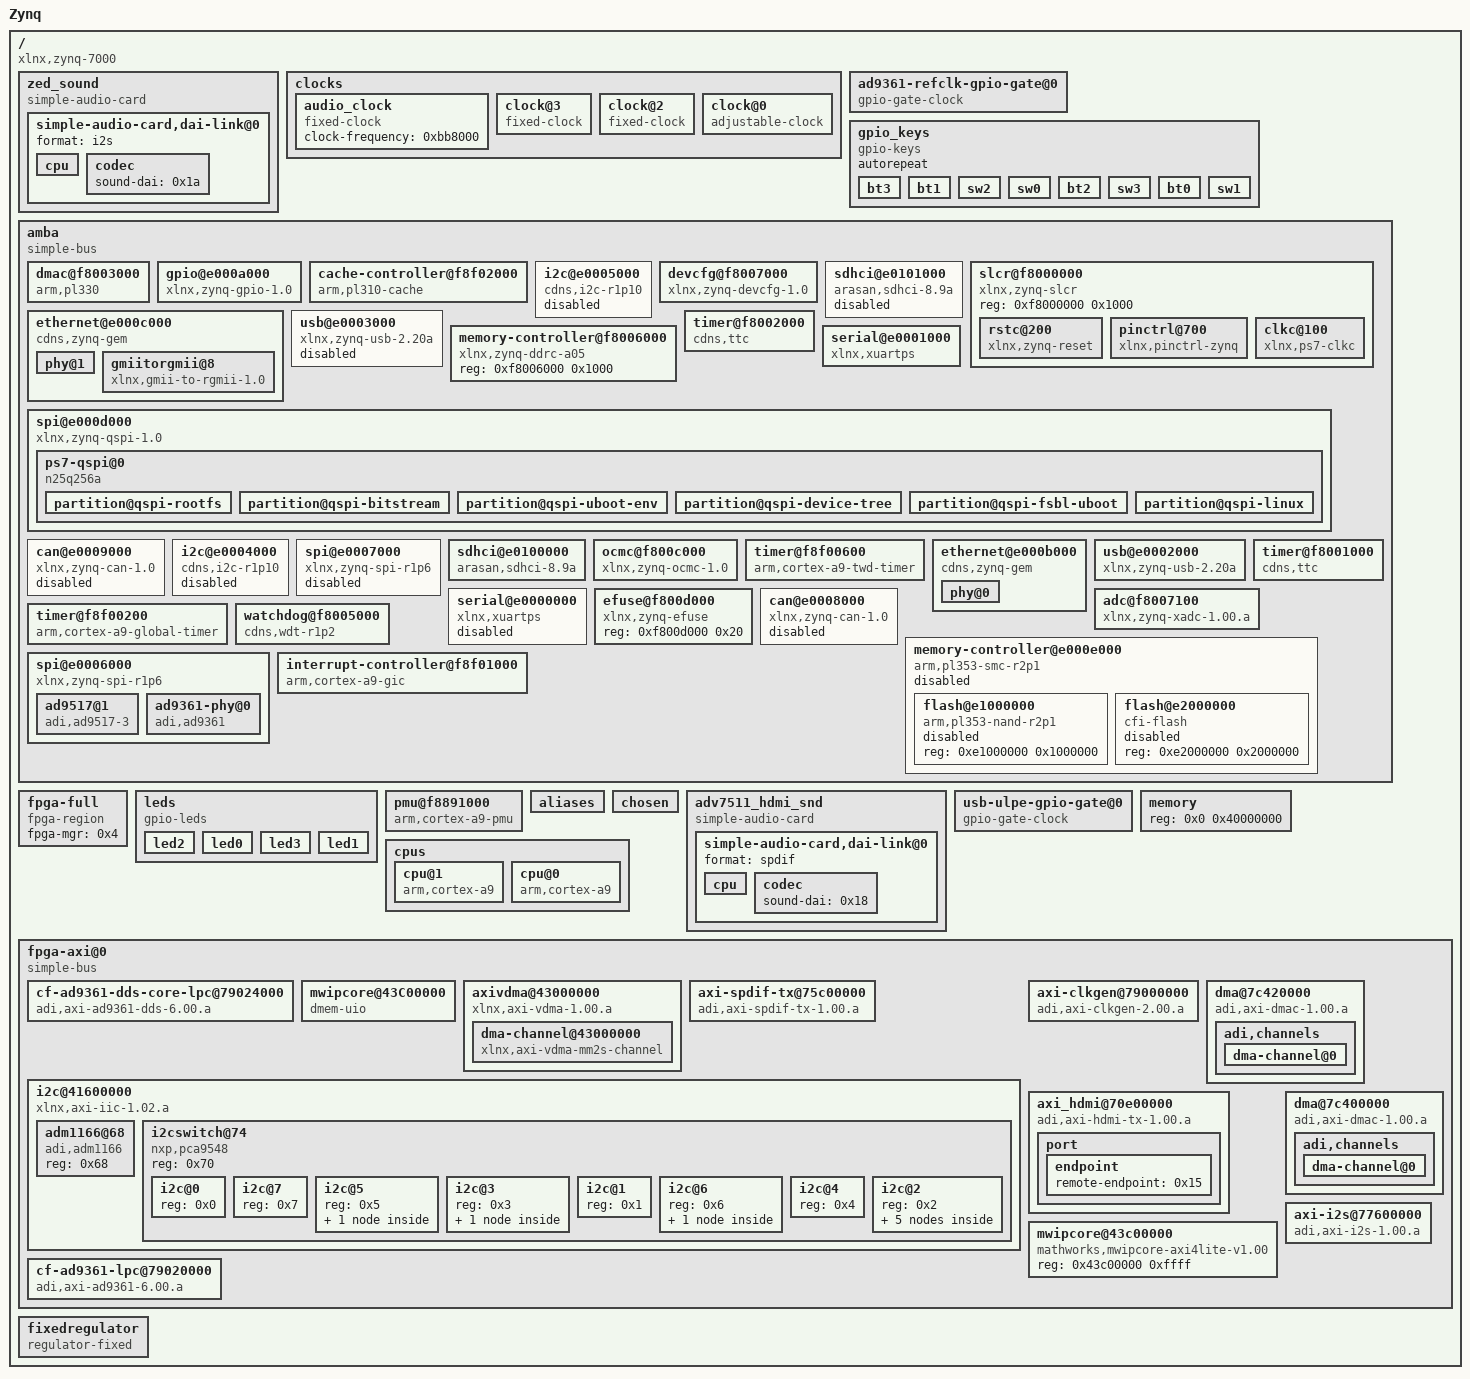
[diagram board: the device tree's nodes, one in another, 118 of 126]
/dts-v1/;

/ {
	compatible = "xlnx,zynq-7000";
	model = "Zynq", "PicoZed", "SDR2", "Board";
	interrupt-parent = <0x1>;
	#address-cells = <0x1>;
	#size-cells = <0x1>;

	zed_sound {
		simple-audio-card,name = "ZED ADAU1761";
		simple-audio-card,routing = "Line Out", "LOUT", "Line Out", "ROUT", "Headphone Out", "LHP", "Headphone Out", "RHP", "Mic In", "MICBIAS", "LINN", "Mic In", "RINN", "Mic In", "LAUX", "Line In", "RAUX", "Line In";
		compatible = "simple-audio-card";
		simple-audio-card,widgets = "Microphone", "Mic In", "Headphone", "Headphone Out", "Line", "Line In", "Line", "Line Out";

		simple-audio-card,dai-link@0 {
			format = "i2s";

			cpu {
				frame-master;
				bitclock-master;
				sound-dai = <0x19>;
			};

			codec {
				sound-dai = <0x1a>;
			};
		};
	};

	clocks {

		audio_clock {
			compatible = "fixed-clock";
			#clock-cells = <0x0>;
			phandle = <0xf>;
			clock-frequency = <0xbb8000>;
			linux,phandle = <0xf>;
		};

		clock@3 {
			compatible = "fixed-clock";
			#clock-cells = <0x0>;
			phandle = <0x7>;
			clock-output-names = "ad9517_refclk";
			clock-frequency = <0x17d7840>;
			linux,phandle = <0x7>;
		};

		clock@2 {
			compatible = "fixed-clock";
			#clock-cells = <0x0>;
			phandle = <0xd>;
			clock-output-names = "24MHz";
			clock-frequency = <0x16e3600>;
			linux,phandle = <0xd>;
		};

		clock@0 {
			compatible = "adjustable-clock";
			#clock-cells = <0x0>;
			phandle = <0xc>;
			clock-accuracy = <0x30d40>;
			clock-output-names = "XO_40MHz";
			clock-frequency = <0x2625976>;
			linux,phandle = <0xc>;
		};
	};

	ad9361-refclk-gpio-gate@0 {
		compatible = "gpio-gate-clock";
		clocks = <0xc>;
		#clock-cells = <0x0>;
		phandle = <0x5>;
		clk-set-rate-parent-enable;
		clock-output-names = "ad9361_ext_refclk";
		linux,phandle = <0x5>;
		enable-gpios = <0x6 0x69 0x0>;
	};

	gpio_keys {
		compatible = "gpio-keys";
		autorepeat;
		#address-cells = <0x1>;
		#size-cells = <0x0>;

		bt3 {
			gpios = <0x6 0x39 0x0>;
			label = "BT3";
			linux,code = <0x1>;
		};

		bt1 {
			gpios = <0x6 0x37 0x0>;
			label = "BT1";
			linux,code = <0x6a>;
		};

		sw2 {
			gpios = <0x6 0x40 0x0>;
			label = "SW2";
			linux,input-type = <0x5>;
			linux,code = <0x2>;
		};

		sw0 {
			gpios = <0x6 0x41 0x0>;
			label = "SW0";
			linux,input-type = <0x5>;
			linux,code = <0x0>;
		};

		bt2 {
			gpios = <0x6 0x38 0x0>;
			label = "BT2";
			linux,code = <0x1c>;
		};

		sw3 {
			gpios = <0x6 0x3f 0x0>;
			label = "SW3";
			linux,input-type = <0x5>;
			linux,code = <0x3>;
		};

		bt0 {
			gpios = <0x6 0x36 0x0>;
			label = "BT0";
			linux,code = <0x69>;
		};

		sw1 {
			gpios = <0x6 0x3e 0x0>;
			label = "SW1";
			linux,input-type = <0x5>;
			linux,code = <0x1>;
		};
	};

	amba {
		compatible = "simple-bus";
		ranges;
		interrupt-parent = <0x1>;
		#address-cells = <0x1>;
		#size-cells = <0x1>;
		u-boot,dm-pre-reloc;

		dmac@f8003000 {
			#dma-cells = <0x1>;
			compatible = "arm,pl330", "arm,primecell";
			clocks = <0x2 0x1b>;
			clock-names = "apb_pclk";
			#dma-requests = <0x4>;
			interrupt-parent = <0x1>;
			interrupts = <0x0 0xd 0x4 0x0 0xe 0x4 0x0 0xf 0x4 0x0 0x10 0x4 0x0 0x11 0x4 0x0 0x28 0x4 0x0 0x29 0x4 0x0 0x2a 0x4 0x0 0x2b 0x4>;
			phandle = <0x16>;
			reg = <0xf8003000 0x1000>;
			linux,phandle = <0x16>;
			#dma-channels = <0x8>;
			interrupt-names = "abort", "dma0", "dma1", "dma2", "dma3", "dma4", "dma5", "dma6", "dma7";
		};

		gpio@e000a000 {
			compatible = "xlnx,zynq-gpio-1.0";
			clocks = <0x2 0x2a>;
			gpio-controller;
			#interrupt-cells = <0x2>;
			interrupt-parent = <0x1>;
			interrupts = <0x0 0x14 0x4>;
			phandle = <0x6>;
			reg = <0xe000a000 0x1000>;
			#gpio-cells = <0x2>;
			linux,phandle = <0x6>;
			interrupt-controller;
		};

		cache-controller@f8f02000 {
			compatible = "arm,pl310-cache";
			cache-level = <0x2>;
			cache-unified;
			arm,data-latency = <0x3 0x2 0x2>;
			interrupts = <0x0 0x2 0x4>;
			reg = <0xf8f02000 0x1000>;
			arm,tag-latency = <0x2 0x2 0x2>;
		};

		i2c@e0005000 {
			compatible = "cdns,i2c-r1p10";
			clocks = <0x2 0x27>;
			status = "disabled";
			interrupt-parent = <0x1>;
			#address-cells = <0x1>;
			interrupts = <0x0 0x30 0x4>;
			#size-cells = <0x0>;
			reg = <0xe0005000 0x1000>;
		};

		devcfg@f8007000 {
			compatible = "xlnx,zynq-devcfg-1.0";
			clocks = <0x2 0xc 0x2 0xf 0x2 0x10 0x2 0x11 0x2 0x12>;
			clock-names = "ref_clk", "fclk0", "fclk1", "fclk2", "fclk3";
			interrupt-parent = <0x1>;
			interrupts = <0x0 0x8 0x4>;
			phandle = <0x4>;
			reg = <0xf8007000 0x100>;
			syscon = <0xb>;
			linux,phandle = <0x4>;
		};

		sdhci@e0101000 {
			compatible = "arasan,sdhci-8.9a";
			clocks = <0x2 0x16 0x2 0x21>;
			clock-names = "clk_xin", "clk_ahb";
			status = "disabled";
			interrupt-parent = <0x1>;
			interrupts = <0x0 0x2f 0x4>;
			reg = <0xe0101000 0x1000>;
			broken-adma2;
		};

		slcr@f8000000 {
			compatible = "xlnx,zynq-slcr", "syscon", "simple-mfd";
			ranges;
			#address-cells = <0x1>;
			#size-cells = <0x1>;
			phandle = <0xb>;
			reg = <0xf8000000 0x1000>;
			linux,phandle = <0xb>;

			rstc@200 {
				compatible = "xlnx,zynq-reset";
				#reset-cells = <0x1>;
				reg = <0x200 0x48>;
				syscon = <0xb>;
			};

			pinctrl@700 {
				compatible = "xlnx,pinctrl-zynq";
				reg = <0x700 0x200>;
				syscon = <0xb>;
			};

			clkc@100 {
				compatible = "xlnx,ps7-clkc";
				ps-clk-frequency = <0x1fca055>;
				#clock-cells = <0x1>;
				phandle = <0x2>;
				reg = <0x100 0x100>;
				clock-output-names = "armpll", "ddrpll", "iopll", "cpu_6or4x", "cpu_3or2x", "cpu_2x", "cpu_1x", "ddr2x", "ddr3x", "dci", "lqspi", "smc", "pcap", "gem0", "gem1", "fclk0", "fclk1", "fclk2", "fclk3", "can0", "can1", "sdio0", "sdio1", "uart0", "uart1", "spi0", "spi1", "dma", "usb0_aper", "usb1_aper", "gem0_aper", "gem1_aper", "sdio0_aper", "sdio1_aper", "spi0_aper", "spi1_aper", "can0_aper", "can1_aper", "i2c0_aper", "i2c1_aper", "uart0_aper", "uart1_aper", "gpio_aper", "lqspi_aper", "smc_aper", "swdt", "dbg_trc", "dbg_apb";
				fclk-enable = <0xf>;
				linux,phandle = <0x2>;
			};
		};

		ethernet@e000c000 {
			phy-handle = <0x9>;
			compatible = "cdns,zynq-gem", "cdns,gem";
			clocks = <0x2 0x1f 0x2 0x1f 0x2 0xe>;
			clock-names = "pclk", "hclk", "tx_clk";
			status = "okay";
			#address-cells = <0x1>;
			interrupts = <0x0 0x2d 0x4>;
			#size-cells = <0x0>;
			reg = <0xe000c000 0x1000>;
			phy-mode = "gmii";

			phy@1 {
				device_type = "ethernet-phy";
				phandle = <0xa>;
				marvell,reg-init = <0x3 0x10 0xff00 0x1e 0x3 0x11 0xfff0 0x0>;
				reg = <0x1>;
				linux,phandle = <0xa>;
			};

			gmiitorgmii@8 {
				phy-handle = <0xa>;
				compatible = "xlnx,gmii-to-rgmii-1.0";
				phandle = <0x9>;
				reg = <0x8>;
				linux,phandle = <0x9>;
			};
		};

		usb@e0003000 {
			compatible = "xlnx,zynq-usb-2.20a", "chipidea,usb2";
			clocks = <0x2 0x1d>;
			status = "disabled";
			interrupt-parent = <0x1>;
			interrupts = <0x0 0x2c 0x4>;
			reg = <0xe0003000 0x1000>;
			phy_type = "ulpi";
		};

		memory-controller@f8006000 {
			compatible = "xlnx,zynq-ddrc-a05";
			reg = <0xf8006000 0x1000>;
		};

		timer@f8002000 {
			compatible = "cdns,ttc";
			clocks = <0x2 0x6>;
			interrupt-parent = <0x1>;
			interrupts = <0x0 0x25 0x4 0x0 0x26 0x4 0x0 0x27 0x4>;
			reg = <0xf8002000 0x1000>;
		};

		serial@e0001000 {
			compatible = "xlnx,xuartps", "cdns,uart-r1p8";
			clocks = <0x2 0x18 0x2 0x29>;
			clock-names = "uart_clk", "pclk";
			status = "okay";
			interrupts = <0x0 0x32 0x4>;
			reg = <0xe0001000 0x1000>;
		};

		spi@e000d000 {
			compatible = "xlnx,zynq-qspi-1.0";
			clocks = <0x2 0xa 0x2 0x2b>;
			clock-names = "ref_clk", "pclk";
			status = "okay";
			interrupt-parent = <0x1>;
			#address-cells = <0x1>;
			interrupts = <0x0 0x13 0x4>;
			#size-cells = <0x0>;
			is-dual = <0x0>;
			reg = <0xe000d000 0x1000>;
			num-cs = <0x1>;

			ps7-qspi@0 {
				compatible = "n25q256a", "jedec,spi-nor";
				spi-rx-bus-width = <0x4>;
				#address-cells = <0x1>;
				#size-cells = <0x1>;
				reg = <0x0>;
				spi-tx-bus-width = <0x1>;
				spi-max-frequency = <0x2faf080>;

				partition@qspi-rootfs {
					label = "qspi-rootfs";
					reg = <0x620000 0xce0000>;
				};

				partition@qspi-bitstream {
					label = "qspi-bitstream";
					reg = <0x1300000 0xd00000>;
				};

				partition@qspi-uboot-env {
					label = "qspi-uboot-env";
					reg = <0xe0000 0x20000>;
				};

				partition@qspi-device-tree {
					label = "qspi-device-tree";
					reg = <0x600000 0x20000>;
				};

				partition@qspi-fsbl-uboot {
					label = "qspi-fsbl-uboot";
					reg = <0x0 0xe0000>;
				};

				partition@qspi-linux {
					label = "qspi-linux";
					reg = <0x100000 0x500000>;
				};
			};
		};

		can@e0009000 {
			compatible = "xlnx,zynq-can-1.0";
			clocks = <0x2 0x14 0x2 0x25>;
			tx-fifo-depth = <0x40>;
			clock-names = "can_clk", "pclk";
			status = "disabled";
			interrupt-parent = <0x1>;
			interrupts = <0x0 0x33 0x4>;
			reg = <0xe0009000 0x1000>;
			rx-fifo-depth = <0x40>;
		};

		i2c@e0004000 {
			compatible = "cdns,i2c-r1p10";
			clocks = <0x2 0x26>;
			status = "disabled";
			interrupt-parent = <0x1>;
			#address-cells = <0x1>;
			interrupts = <0x0 0x19 0x4>;
			#size-cells = <0x0>;
			reg = <0xe0004000 0x1000>;
		};

		spi@e0007000 {
			compatible = "xlnx,zynq-spi-r1p6";
			clocks = <0x2 0x1a 0x2 0x23>;
			clock-names = "ref_clk", "pclk";
			status = "disabled";
			interrupt-parent = <0x1>;
			#address-cells = <0x1>;
			interrupts = <0x0 0x31 0x4>;
			#size-cells = <0x0>;
			reg = <0xe0007000 0x1000>;
		};

		sdhci@e0100000 {
			compatible = "arasan,sdhci-8.9a";
			clocks = <0x2 0x15 0x2 0x20>;
			clock-names = "clk_xin", "clk_ahb";
			status = "okay";
			interrupt-parent = <0x1>;
			interrupts = <0x0 0x18 0x4>;
			disable-wp;
			reg = <0xe0100000 0x1000>;
			broken-adma2;
		};

		ocmc@f800c000 {
			compatible = "xlnx,zynq-ocmc-1.0";
			interrupt-parent = <0x1>;
			interrupts = <0x0 0x3 0x4>;
			reg = <0xf800c000 0x1000>;
		};

		timer@f8f00600 {
			compatible = "arm,cortex-a9-twd-timer";
			clocks = <0x2 0x4>;
			interrupt-parent = <0x1>;
			interrupts = <0x1 0xd 0x301>;
			reg = <0xf8f00600 0x20>;
		};

		ethernet@e000b000 {
			phy-handle = <0x8>;
			compatible = "cdns,zynq-gem", "cdns,gem";
			clocks = <0x2 0x1e 0x2 0x1e 0x2 0xd>;
			local-mac-address = [00 02 b5 01 c5 57];
			clock-names = "pclk", "hclk", "tx_clk";
			status = "okay";
			#address-cells = <0x1>;
			interrupts = <0x0 0x16 0x4>;
			#size-cells = <0x0>;
			reg = <0xe000b000 0x1000>;
			phy-mode = "rgmii-id";

			phy@0 {
				device_type = "ethernet-phy";
				phandle = <0x8>;
				marvell,reg-init = <0x3 0x10 0xff00 0x1e 0x3 0x11 0xfff0 0x0>;
				reg = <0x0>;
				linux,phandle = <0x8>;
			};
		};

		usb@e0002000 {
			compatible = "xlnx,zynq-usb-2.20a", "chipidea,usb2";
			clocks = <0x2 0x1c>;
			status = "okay";
			interrupt-parent = <0x1>;
			interrupts = <0x0 0x15 0x4>;
			xlnx,phy-reset-gpio = <0x6 0x7 0x0>;
			reg = <0xe0002000 0x1000>;
			dr_mode = "host";
			phy_type = "ulpi";
		};

		timer@f8001000 {
			compatible = "cdns,ttc";
			clocks = <0x2 0x6>;
			interrupt-parent = <0x1>;
			interrupts = <0x0 0xa 0x4 0x0 0xb 0x4 0x0 0xc 0x4>;
			reg = <0xf8001000 0x1000>;
		};

		serial@e0000000 {
			compatible = "xlnx,xuartps", "cdns,uart-r1p8";
			clocks = <0x2 0x17 0x2 0x28>;
			clock-names = "uart_clk", "pclk";
			status = "disabled";
			interrupts = <0x0 0x1b 0x4>;
			reg = <0xe0000000 0x1000>;
		};

		efuse@f800d000 {
			compatible = "xlnx,zynq-efuse";
			reg = <0xf800d000 0x20>;
		};

		can@e0008000 {
			compatible = "xlnx,zynq-can-1.0";
			clocks = <0x2 0x13 0x2 0x24>;
			tx-fifo-depth = <0x40>;
			clock-names = "can_clk", "pclk";
			status = "disabled";
			interrupt-parent = <0x1>;
			interrupts = <0x0 0x1c 0x4>;
			reg = <0xe0008000 0x1000>;
			rx-fifo-depth = <0x40>;
		};

		adc@f8007100 {
			compatible = "xlnx,zynq-xadc-1.00.a";
			clocks = <0x2 0xc>;
			interrupt-parent = <0x1>;
			interrupts = <0x0 0x7 0x4>;
			reg = <0xf8007100 0x20>;
		};

		timer@f8f00200 {
			compatible = "arm,cortex-a9-global-timer";
			clocks = <0x2 0x4>;
			interrupt-parent = <0x1>;
			interrupts = <0x1 0xb 0x301>;
			reg = <0xf8f00200 0x20>;
		};

		memory-controller@e000e000 {
			compatible = "arm,pl353-smc-r2p1";
			clocks = <0x2 0xb 0x2 0x2c>;
			clock-names = "memclk", "aclk";
			ranges;
			status = "disabled";
			interrupt-parent = <0x1>;
			#address-cells = <0x1>;
			interrupts = <0x0 0x12 0x4>;
			#size-cells = <0x1>;
			reg = <0xe000e000 0x1000>;

			flash@e1000000 {
				compatible = "arm,pl353-nand-r2p1";
				status = "disabled";
				#address-cells = <0x1>;
				#size-cells = <0x1>;
				reg = <0xe1000000 0x1000000>;
			};

			flash@e2000000 {
				compatible = "cfi-flash";
				status = "disabled";
				#address-cells = <0x1>;
				#size-cells = <0x1>;
				reg = <0xe2000000 0x2000000>;
			};
		};

		watchdog@f8005000 {
			compatible = "cdns,wdt-r1p2";
			clocks = <0x2 0x2d>;
			interrupt-parent = <0x1>;
			interrupts = <0x0 0x9 0x1>;
			reg = <0xf8005000 0x1000>;
			timeout-sec = <0xa>;
		};

		spi@e0006000 {
			compatible = "xlnx,zynq-spi-r1p6";
			clocks = <0x2 0x19 0x2 0x22>;
			clock-names = "ref_clk", "pclk";
			status = "okay";
			interrupt-parent = <0x1>;
			#address-cells = <0x1>;
			interrupts = <0x0 0x1a 0x4>;
			#size-cells = <0x0>;
			reg = <0xe0006000 0x1000>;

			ad9517@1 {
				compatible = "adi,ad9517-3";
				clocks = <0x7 0x7>;
				clock-names = "refclk", "clkin";
				firmware = "pzsdr-fmc-ad9517.stp";
				#address-cells = <0x1>;
				#size-cells = <0x0>;
				#clock-cells = <0x1>;
				reg = <0x1>;
				clock-output-names = "out0", "out1", "out2", "out3", "out4", "out5", "out6", "out7";
				spi-max-frequency = <0x989680>;
			};

			ad9361-phy@0 {
				adi,mgc-inc-gain-step = <0x2>;
				adi,rf-rx-bandwidth-hz = <0x112a880>;
				adi,gc-dec-pow-measurement-duration = <0x2000>;
				adi,agc-adc-large-overload-exceed-counter = <0xa>;
				adi,pp-tx-swap-enable;
				adi,rssi-wait = <0x1>;
				adi,aux-dac-manual-mode-enable;
				compatible = "adi,ad9361";
				adi,gc-adc-small-overload-thresh = <0x2f>;
				clocks = <0x5 0x0>;
				adi,agc-lmt-overload-large-exceed-counter = <0xa>;
				adi,temp-sense-offset-signed = <0xce>;
				adi,gc-rx1-mode = <0x2>;
				adi,2rx-2tx-mode-enable;
				adi,fagc-use-last-lock-level-for-set-gain-enable;
				adi,lvds-bias-mV = <0x96>;
				en_agc-gpios = <0x6 0x62 0x0>;
				adi,fagc-rst-gla-engergy-lost-goto-optim-gain-enable;
				adi,fagc-rst-gla-large-adc-overload-enable;
				adi,rssi-duration = <0x3e8>;
				adi,mgc-dec-gain-step = <0x2>;
				adi,fagc-lpf-final-settling-steps = <0x1>;
				adi,fagc-rst-gla-large-lmt-overload-enable;
				adi,aux-dac2-default-value-mV = <0x0>;
				spi-cpha;
				adi,fagc-final-overrange-count = <0x3>;
				adi,fagc-lock-level-gain-increase-upper-limit = <0x5>;
				adi,tx-synthesizer-frequency-hz = <0x0 0x92080880>;
				adi,agc-attack-delay-extra-margin-us = <0x1>;
				adi,rx-data-delay = <0x4>;
				adi,fagc-rst-gla-engergy-lost-sig-thresh-exceeded-enable;
				clock-names = "ad9361_ext_refclk";
				adi,tx-path-clock-frequencies = <0x3a980000 0x7530000 0x7530000 0x3a98000 0x1d4c000 0x1d4c000>;
				adi,agc-lmt-overload-small-exceed-counter = <0xa>;
				adi,temp-sense-periodic-measurement-enable;
				adi,fagc-state-wait-time-ns = <0x104>;
				adi,fagc-gain-index-type-after-exit-rx-mode = <0x0>;
				adi,tx-fb-clock-delay = <0x7>;
				adi,fagc-dec-pow-measurement-duration = <0x40>;
				adi,gc-adc-large-overload-thresh = <0x3a>;
				txnrx-gpios = <0x6 0x66 0x0>;
				adi,rssi-restart-mode = <0x3>;
				adi,fagc-power-measurement-duration-in-state5 = <0x40>;
				adi,ctrl-outs-enable-mask = <0xff>;
				adi,rf-tx-bandwidth-hz = <0x112a880>;
				adi,fagc-lp-thresh-increment-time = <0x5>;
				adi,aux-dac1-tx-delay-us = <0x0>;
				adi,tx-rf-port-input-select = <0x0>;
				adi,agc-outer-thresh-low-inc-steps = <0x2>;
				#address-cells = <0x1>;
				adi,rx-synthesizer-frequency-hz = <0x0 0x8f0d1800>;
				reset-gpios = <0x6 0x64 0x0>;
				adi,fagc-rst-gla-if-en-agc-pulled-high-mode = <0x0>;
				adi,rx-frame-pulse-mode-enable;
				#size-cells = <0x0>;
				adi,agc-inner-thresh-low-inc-steps = <0x1>;
				adi,pp-rx-swap-enable;
				#clock-cells = <0x1>;
				adi,rx-path-clock-frequencies = <0x3a980000 0xea60000 0x7530000 0x3a98000 0x1d4c000 0x1d4c000>;
				phandle = <0x11>;
				adi,fagc-lp-thresh-increment-steps = <0x1>;
				adi,aux-dac1-default-value-mV = <0x0>;
				adi,fagc-rst-gla-stronger-sig-thresh-above-ll = <0xa>;
				adi,fagc-energy-lost-stronger-sig-gain-lock-exit-cnt = <0x8>;
				adi,tx-attenuation-mdB = <0x2710>;
				adi,digital-interface-tune-skip-mode = <0x0>;
				adi,agc-inner-thresh-high = <0xa>;
				adi,ctrl-outs-index = <0x0>;
				adi,agc-gain-update-interval-us = <0x3e8>;
				adi,aux-dac2-tx-delay-us = <0x0>;
				adi,fagc-optimized-gain-offset = <0x5>;
				adi,fagc-rst-gla-stronger-sig-thresh-exceeded-enable;
				adi,agc-inner-thresh-high-dec-steps = <0x1>;
				adi,aux-dac1-rx-delay-us = <0x0>;
				reg = <0x0>;
				adi,gc-low-power-thresh = <0x18>;
				adi,xo-disable-use-ext-refclk-enable;
				adi,agc-outer-thresh-low = <0x12>;
				clock-output-names = "rx_sampl_clk", "tx_sampl_clk";
				adi,mgc-split-table-ctrl-inp-gain-mode = <0x0>;
				adi,fagc-lmt-final-settling-steps = <0x1>;
				adi,lvds-mode-enable;
				adi,gc-lmt-overload-high-thresh = <0x320>;
				adi,agc-lmt-overload-large-inc-steps = <0x2>;
				adi,fagc-lock-level-lmt-gain-increase-enable;
				adi,rx-rf-port-input-select = <0x0>;
				adi,agc-inner-thresh-low = <0xc>;
				adi,fagc-rst-gla-engergy-lost-sig-thresh-below-ll = <0xa>;
				adi,agc-outer-thresh-high-dec-steps = <0x2>;
				adi,lvds-rx-onchip-termination-enable;
				linux,phandle = <0x11>;
				sync-gpios = <0x6 0x63 0x0>;
				enable-gpios = <0x6 0x65 0x0>;
				spi-max-frequency = <0x989680>;
				adi,rssi-delay = <0x1>;
				adi,agc-outer-thresh-high = <0x5>;
				adi,frequency-division-duplex-mode-enable;
				adi,aux-dac2-rx-delay-us = <0x0>;
				adi,agc-adc-large-overload-inc-steps = <0x2>;
				adi,gc-lmt-overload-low-thresh = <0x2c0>;
				adi,gc-adc-ovr-sample-size = <0x4>;
				adi,gc-rx2-mode = <0x2>;
				adi,temp-sense-measurement-interval-ms = <0x3e8>;
				adi,fagc-lock-level = <0xa>;
				adi,agc-adc-small-overload-exceed-counter = <0xa>;
			};
		};

		interrupt-controller@f8f01000 {
			compatible = "arm,cortex-a9-gic";
			#interrupt-cells = <0x3>;
			phandle = <0x1>;
			reg = <0xf8f01000 0x1000 0xf8f00100 0x100>;
			linux,phandle = <0x1>;
			interrupt-controller;
		};
	};

	fpga-full {
		compatible = "fpga-region";
		fpga-mgr = <0x4>;
		ranges;
		#address-cells = <0x1>;
		#size-cells = <0x1>;
	};

	leds {
		compatible = "gpio-leds";

		led2 {
			gpios = <0x6 0x3a 0x0>;
			label = "led2:red";
		};

		led0 {
			gpios = <0x6 0x3d 0x0>;
			label = "led0:red";
		};

		led3 {
			gpios = <0x6 0x3c 0x0>;
			label = "led3:red";
		};

		led1 {
			gpios = <0x6 0x3b 0x0>;
			label = "led1:red";
		};
	};

	pmu@f8891000 {
		compatible = "arm,cortex-a9-pmu";
		interrupt-parent = <0x1>;
		interrupts = <0x0 0x5 0x4 0x0 0x6 0x4>;
		reg = <0xf8891000 0x1000 0xf8893000 0x1000>;
	};

	aliases {
		ethernet0 = "/amba/ethernet@e000b000";
		ethernet1 = "/amba/ethernet@e000c000";
		serial0 = "/amba/serial@e0001000";
	};

	chosen {
		bootargs = "console=ttyPS0,115200 root=/dev/mmcblk0p2 rw earlyprintk rootfstype=ext4 rootwait";
		linux,stdout-path = "/amba@0/uart@E0001000";
	};

	adv7511_hdmi_snd {
		simple-audio-card,name = "HDMI monitor";
		simple-audio-card,routing = "Speaker", "TX";
		compatible = "simple-audio-card";
		simple-audio-card,widgets = "Speaker", "Speaker";

		simple-audio-card,dai-link@0 {
			format = "spdif";

			cpu {
				frame-master;
				bitclock-master;
				sound-dai = <0x17>;
			};

			codec {
				sound-dai = <0x18>;
			};
		};
	};

	usb-ulpe-gpio-gate@0 {
		compatible = "gpio-gate-clock";
		clocks = <0xd>;
		#clock-cells = <0x0>;
		enable-gpios = <0x6 0x9 0x1>;
	};

	memory {
		device_type = "memory";
		reg = <0x0 0x40000000>;
	};

	cpus {
		#address-cells = <0x1>;
		#size-cells = <0x0>;

		cpu@1 {
			compatible = "arm,cortex-a9";
			clocks = <0x2 0x3>;
			device_type = "cpu";
			reg = <0x1>;
		};

		cpu@0 {
			compatible = "arm,cortex-a9";
			clocks = <0x2 0x3>;
			device_type = "cpu";
			cpu0-supply = <0x3>;
			reg = <0x0>;
			operating-points = <0xa2c2b 0xf4240 0x51616 0xf4240>;
			clock-latency = <0x3e8>;
		};
	};

	fpga-axi@0 {
		compatible = "simple-bus";
		ranges;
		#address-cells = <0x1>;
		#size-cells = <0x1>;

		cf-ad9361-dds-core-lpc@79024000 {
			compatible = "adi,axi-ad9361-dds-6.00.a";
			clocks = <0x11 0xd>;
			clock-names = "sampl_clk";
			dma-names = "tx";
			reg = <0x79024000 0x1000>;
			dmas = <0x12 0x0>;
		};

                mwipcore@43C00000 {
                        compatible = "dmem-uio";
                        interrupts = <0x0 0x37 0x0>;
                        reg = <0x43c00000 0xffff>;
                };

		axivdma@43000000 {
			xlnx,num-fstores = <0x3>;
			#dma-cells = <0x1>;
			compatible = "xlnx,axi-vdma-1.00.a";
			#address-cells = <0x1>;
			#size-cells = <0x1>;
			phandle = <0x13>;
			reg = <0x43000000 0x1000>;
			linux,phandle = <0x13>;
			#dma-channels = <0x1>;

			dma-channel@43000000 {
				compatible = "xlnx,axi-vdma-mm2s-channel";
				xlnx,include-dre = <0x0>;
				xlnx,genlock-mode = <0x0>;
				interrupts = <0x0 0x3b 0x4>;
				xlnx,datawidth = <0x40>;
			};
		};

		axi-spdif-tx@75c00000 {
			compatible = "adi,axi-spdif-tx-1.00.a";
			clocks = <0x2 0xf 0xf>;
			#sound-dai-cells = <0x0>;
			clock-names = "axi", "ref";
			dma-names = "tx";
			phandle = <0x17>;
			reg = <0x75c00000 0x1000>;
			dmas = <0x16 0x0>;
			linux,phandle = <0x17>;
		};

		i2c@41600000 {
			compatible = "xlnx,axi-iic-1.02.a", "xlnx,xps-iic-2.00.a";
			clocks = <0x2 0xf>;
			clock-names = "pclk";
			interrupt-parent = <0x1>;
			#address-cells = <0x1>;
			interrupts = <0x0 0x3a 0x4>;
			#size-cells = <0x0>;
			reg = <0x41600000 0x10000>;

			adm1166@68 {
				compatible = "adi,adm1166";
				reg = <0x68>;
			};

			i2cswitch@74 {
				compatible = "nxp,pca9548";
				#address-cells = <0x1>;
				#size-cells = <0x0>;
				reg = <0x70>;

				i2c@0 {
					#address-cells = <0x1>;
					#size-cells = <0x0>;
					reg = <0x0>;
				};

				i2c@7 {
					#address-cells = <0x1>;
					#size-cells = <0x0>;
					reg = <0x7>;
				};

				i2c@5 {
					#address-cells = <0x1>;
					#size-cells = <0x0>;
					reg = <0x5>;

					eeprom@50 {
						compatible = "at24,24c32";
						reg = <0x50>;
					};
				};

				i2c@3 {
					#address-cells = <0x1>;
					#size-cells = <0x0>;
					reg = <0x3>;

					adau1761@3b {
						compatible = "adi,adau1761";
						clocks = <0xf>;
						#sound-dai-cells = <0x0>;
						clock-names = "mclk";
						phandle = <0x1a>;
						reg = <0x3b>;
						linux,phandle = <0x1a>;
					};
				};

				i2c@1 {
					#address-cells = <0x1>;
					#size-cells = <0x0>;
					reg = <0x1>;
				};

				i2c@6 {
					#address-cells = <0x1>;
					#size-cells = <0x0>;
					reg = <0x6>;

					ad7291@2f {
						compatible = "adi,ad7291";
						reg = <0x2f>;
					};
				};

				i2c@4 {
					#address-cells = <0x1>;
					#size-cells = <0x0>;
					reg = <0x4>;
				};

				i2c@2 {
					#address-cells = <0x1>;
					#size-cells = <0x0>;
					reg = <0x2>;

					adv7511@39 {
						compatible = "adi,adv7511";
						#sound-dai-cells = <0x0>;
						reg-names = "primary", "edid";
						adi,input-depth = <0x8>;
						adi,input-justification = "left";
						adi,input-style = <0x1>;
						adi,input-colorspace = "yuv422";
						adi,input-clock = "1x";
						phandle = <0x18>;
						adi,clock-delay = <0x0>;
						reg = <0x39 0x3f>;
						linux,phandle = <0x18>;

						ports {
							#address-cells = <0x1>;
							#size-cells = <0x0>;

							port@1 {
								reg = <0x1>;
							};

							port@0 {
								reg = <0x0>;

								endpoint {
									remote-endpoint = <0xe>;
									phandle = <0x15>;
									linux,phandle = <0x15>;
								};
							};
						};
					};
				};
			};
		};

		axi-clkgen@79000000 {
			compatible = "adi,axi-clkgen-2.00.a";
			clocks = <0x2 0x10>;
			#clock-cells = <0x0>;
			phandle = <0x14>;
			reg = <0x79000000 0x10000>;
			linux,phandle = <0x14>;
		};

		dma@7c420000 {
			#dma-cells = <0x1>;
			compatible = "adi,axi-dmac-1.00.a";
			clocks = <0x2 0x10>;
			interrupts = <0x0 0x38 0x0>;
			phandle = <0x12>;
			reg = <0x7c420000 0x10000>;
			linux,phandle = <0x12>;

			adi,channels {
				#address-cells = <0x1>;
				#size-cells = <0x0>;

				dma-channel@0 {
					adi,length-width = <0x18>;
					adi,source-bus-type = <0x0>;
					adi,destination-bus-type = <0x2>;
					adi,cyclic;
					adi,destination-bus-width = <0x40>;
					adi,source-bus-width = <0x40>;
					reg = <0x0>;
				};
			};
		};

		axi_hdmi@70e00000 {
			compatible = "adi,axi-hdmi-tx-1.00.a";
			clocks = <0x14>;
			dma-names = "video";
			reg = <0x70e00000 0x10000>;
			dmas = <0x13 0x0>;

			port {

				endpoint {
					remote-endpoint = <0x15>;
					phandle = <0xe>;
					linux,phandle = <0xe>;
				};
			};
		};

		mwipcore@43c00000 {
			compatible = "mathworks,mwipcore-axi4lite-v1.00";
			reg = <0x43c00000 0xffff>;
		};

		cf-ad9361-lpc@79020000 {
			spibus-connected = <0x11>;
			compatible = "adi,axi-ad9361-6.00.a";
			dma-names = "rx";
			reg = <0x79020000 0x6000>;
			dmas = <0x10 0x0>;
		};

		dma@7c400000 {
			#dma-cells = <0x1>;
			compatible = "adi,axi-dmac-1.00.a";
			clocks = <0x2 0x10>;
			interrupts = <0x0 0x39 0x0>;
			phandle = <0x10>;
			reg = <0x7c400000 0x10000>;
			linux,phandle = <0x10>;

			adi,channels {
				#address-cells = <0x1>;
				#size-cells = <0x0>;

				dma-channel@0 {
					adi,length-width = <0x18>;
					adi,source-bus-type = <0x2>;
					adi,destination-bus-type = <0x0>;
					adi,destination-bus-width = <0x40>;
					adi,source-bus-width = <0x40>;
					reg = <0x0>;
				};
			};
		};

		axi-i2s@77600000 {
			compatible = "adi,axi-i2s-1.00.a";
			clocks = <0x2 0xf 0xf>;
			#sound-dai-cells = <0x0>;
			clock-names = "axi", "ref";
			dma-names = "tx", "rx";
			phandle = <0x19>;
			reg = <0x77600000 0x1000>;
			dmas = <0x16 0x1 0x16 0x2>;
			linux,phandle = <0x19>;
		};
	};

	fixedregulator {
		compatible = "regulator-fixed";
		regulator-boot-on;
		phandle = <0x3>;
		regulator-min-microvolt = <0xf4240>;
		regulator-max-microvolt = <0xf4240>;
		regulator-always-on;
		regulator-name = "VCCPINT";
		linux,phandle = <0x3>;
	};
};
